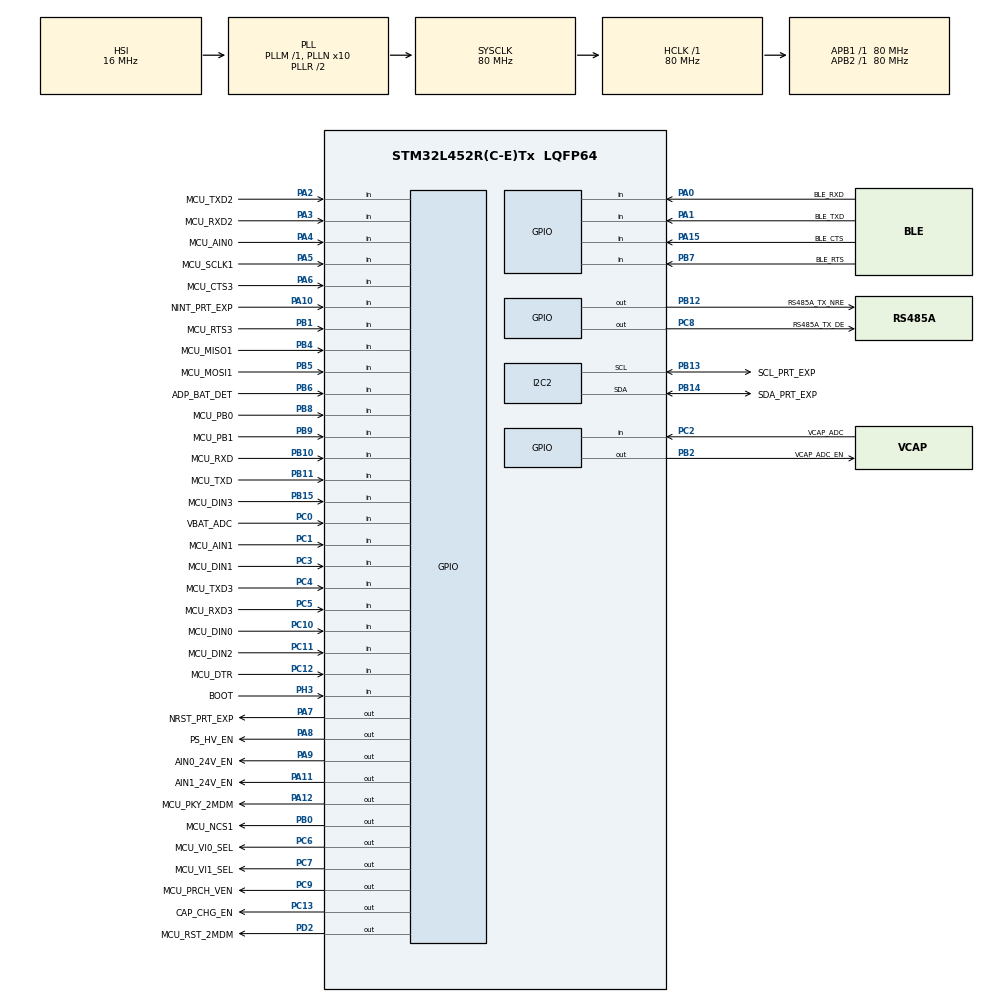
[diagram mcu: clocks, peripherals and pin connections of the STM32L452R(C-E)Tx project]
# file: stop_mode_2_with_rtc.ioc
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I2C2.Speed=10
I2C2.Timing=0xF010F3FE
Mcu.Family=STM32L4
Mcu.Name=STM32L452R(C-E)Tx
Mcu.Package=LQFP64
NVIC.I2C2_ER_IRQn=true\:0\:0\:false\:false\:true\:true\:true
NVIC.I2C2_EV_IRQn=true\:0\:0\:false\:false\:true\:true\:true
NVIC.PriorityGroup=NVIC_PRIORITYGROUP_4
PA0.GPIO_Label=BLE_RXD
PA0.GPIO_PuPd=GPIO_PULLUP
PA0.Signal=GPIO_Input
PA1.GPIO_Label=BLE_TXD
PA1.GPIO_PuPd=GPIO_PULLUP
PA1.Signal=GPIO_Input
PA10.GPIO_Label=NINT_PRT_EXP
PA10.GPIO_PuPd=GPIO_PULLUP
PA10.Signal=GPIO_Input
PA11.GPIO_Label=AIN1_24V_EN
PA11.GPIO_PuPd=GPIO_NOPULL
PA11.PinState=GPIO_PIN_RESET
PA11.Signal=GPIO_Output
PA12.GPIO_Label=MCU_PKY_2MDM
PA12.Signal=GPIO_Output
PA13\ (JTMS/SWDIO).GPIO_Label=TMS
PA13\ (JTMS/SWDIO).Mode=Trace_Asynchronous_SW
PA13\ (JTMS/SWDIO).Signal=SYS_JTMS-SWDIO
PA14\ (JTCK/SWCLK).GPIO_Label=TCK
PA14\ (JTCK/SWCLK).Mode=Trace_Asynchronous_SW
PA14\ (JTCK/SWCLK).Signal=SYS_JTCK-SWCLK
PA15\ (JTDI).GPIO_Label=BLE_CTS
PA15\ (JTDI).GPIO_PuPd=GPIO_PULLUP
PA15\ (JTDI).Signal=GPIO_Input
PA2.GPIO_Label=MCU_TXD2
PA2.GPIO_PuPd=GPIO_PULLUP
PA2.Signal=GPIO_Input
PA3.GPIO_Label=MCU_RXD2
PA3.GPIO_PuPd=GPIO_PULLUP
PA3.Signal=GPIO_Input
PA4.GPIO_Label=MCU_AIN0
PA4.Signal=GPIO_Input
PA5.GPIO_Label=MCU_SCLK1
PA5.GPIO_PuPd=GPIO_PULLUP
PA5.Signal=GPIO_Input
PA6.GPIO_Label=MCU_CTS3
PA6.GPIO_PuPd=GPIO_PULLUP
PA6.Signal=GPIO_Input
PA7.GPIO_Label=NRST_PRT_EXP
PA7.GPIO_PuPd=GPIO_NOPULL
PA7.GPIO_Speed=GPIO_SPEED_FREQ_LOW
PA7.PinState=GPIO_PIN_SET
PA7.Signal=GPIO_Output
PA8.GPIO_Label=PS_HV_EN
PA8.PinState=GPIO_PIN_RESET
PA8.Signal=GPIO_Output
PA9.GPIO_Label=AIN0_24V_EN
PA9.Signal=GPIO_Output
PB0.GPIO_Label=MCU_NCS1
PB0.PinState=GPIO_PIN_SET
PB0.Signal=GPIO_Output
PB1.GPIO_Label=MCU_RTS3
PB1.GPIO_PuPd=GPIO_PULLUP
PB1.Signal=GPIO_Input
PB10.GPIO_Label=MCU_RXD
PB10.GPIO_PuPd=GPIO_PULLUP
PB10.Signal=GPIO_Input
PB11.GPIO_Label=MCU_TXD
PB11.GPIO_PuPd=GPIO_PULLUP
PB11.Signal=GPIO_Input
PB12.GPIO_Label=RS485A_TX_NRE
PB12.PinState=GPIO_PIN_SET
PB12.Signal=GPIO_Output
PB13.GPIO_Label=SCL_PRT_EXP
PB13.Mode=I2C
PB13.Signal=I2C2_SCL
PB14.GPIO_Label=SDA_PRT_EXP
PB14.Mode=I2C
PB14.Signal=I2C2_SDA
PB15.GPIO_Label=MCU_DIN3
PB15.GPIO_PuPd=GPIO_PULLUP
PB15.Signal=GPIO_Input
PB2.GPIO_Label=VCAP_ADC_EN
PB2.Signal=GPIO_Output
PB3\ (JTDO/TRACESWO).GPIO_Label=SWO
PB3\ (JTDO/TRACESWO).Mode=Trace_Asynchronous_SW
PB3\ (JTDO/TRACESWO).Signal=SYS_JTDO-SWO
PB4\ (NJTRST).GPIO_Label=MCU_MISO1
PB4\ (NJTRST).GPIO_PuPd=GPIO_PULLUP
PB4\ (NJTRST).Signal=GPIO_Input
PB5.GPIO_Label=MCU_MOSI1
PB5.GPIO_PuPd=GPIO_PULLUP
PB5.Signal=GPIO_Input
PB6.GPIO_Label=ADP_BAT_DET
PB6.Signal=GPIO_Input
PB7.GPIO_Label=BLE_RTS
PB7.GPIO_PuPd=GPIO_PULLUP
PB7.Signal=GPIO_Input
PB8.GPIO_Label=MCU_PB0
PB8.GPIO_PuPd=GPIO_PULLUP
PB8.Signal=GPIO_Input
PB9.GPIO_Label=MCU_PB1
PB9.GPIO_PuPd=GPIO_PULLUP
PB9.Signal=GPIO_Input
PC0.GPIO_Label=VBAT_ADC
PC0.Signal=GPIO_Input
PC1.GPIO_Label=MCU_AIN1
PC1.Signal=GPIO_Input
PC10.GPIO_Label=MCU_DIN0
PC10.GPIO_PuPd=GPIO_PULLUP
PC10.Signal=GPIO_Input
PC11.GPIO_Label=MCU_DIN2
PC11.GPIO_PuPd=GPIO_PULLUP
PC11.Signal=GPIO_Input
PC12.GPIO_Label=MCU_DTR
PC12.GPIO_PuPd=GPIO_PULLUP
PC12.Signal=GPIO_Input
PC13.GPIO_Label=CAP_CHG_EN
PC13.Signal=GPIO_Output
PC14-OSC32_IN\ (PC14).Mode=LSE-External-Oscillator
PC14-OSC32_IN\ (PC14).Signal=RCC_OSC32_IN
PC15-OSC32_OUT\ (PC15).Mode=LSE-External-Oscillator
PC15-OSC32_OUT\ (PC15).Signal=RCC_OSC32_OUT
PC2.GPIO_Label=VCAP_ADC
PC2.Signal=GPIO_Input
PC3.GPIO_Label=MCU_DIN1
PC3.GPIO_PuPd=GPIO_PULLUP
PC3.Signal=GPIO_Input
PC4.GPIO_Label=MCU_TXD3
PC4.GPIO_PuPd=GPIO_PULLUP
PC4.Signal=GPIO_Input
PC5.GPIO_Label=MCU_RXD3
PC5.GPIO_PuPd=GPIO_PULLUP
PC5.Signal=GPIO_Input
PC6.GPIO_Label=MCU_VI0_SEL
PC6.Signal=GPIO_Output
PC7.GPIO_Label=MCU_VI1_SEL
PC7.Signal=GPIO_Output
PC8.GPIO_Label=RS485A_TX_DE
PC8.Signal=GPIO_Output
PC9.GPIO_Label=MCU_PRCH_VEN
PC9.Signal=GPIO_Output
PD2.GPIO_Label=MCU_RST_2MDM
PD2.Signal=GPIO_Output
PH0-OSC_IN\ (PH0).Signal=RCC_OSC_IN
PH1-OSC_OUT\ (PH1).Signal=RCC_OSC_OUT
PH3-BOOT0\ (BOOT0).GPIO_Label=BOOT
PH3-BOOT0\ (BOOT0).Signal=GPIO_Input
ProjectManager.HeapSize=0x200
ProjectManager.StackSize=0x400
ProjectManager.TargetToolchain=STM32CubeIDE
RCC.ADCFreq_Value=64000000
RCC.AHBFreq_Value=80000000
RCC.APB1Freq_Value=80000000
RCC.APB1TimFreq_Value=80000000
RCC.APB2Freq_Value=80000000
RCC.APB2TimFreq_Value=80000000
RCC.CortexFreq_Value=80000000
RCC.HCLKFreq_Value=80000000
RCC.HSE_VALUE=8000000
RCC.HSI48_VALUE=48000000
RCC.HSI_VALUE=16000000
RCC.MSI_VALUE=4000000
RCC.PLLN=10
RCC.PLLSourceVirtual=RCC_PLLSOURCE_HSI
RCC.PREFETCH_ENABLE=1
RCC.SYSCLKFreq_VALUE=80000000
RCC.SYSCLKSource=RCC_SYSCLKSOURCE_PLLCLK
RCC.USBFreq_Value=64000000
RCC.VCOOutputFreq_Value=160000000
board=NUCLEO-L452RE

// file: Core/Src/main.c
/* USER CODE BEGIN Header */
/**
  ******************************************************************************
  * @file           : main.c
  * @brief          : Main program body
  ******************************************************************************
  * @attention
  *
  * <h2><center>&copy; Copyright (c) 2020 STMicroelectronics.
  * All rights reserved.</center></h2>
  *
  * This software component is licensed by ST under BSD 3-Clause license,
  * the "License"; You may not use this file except in compliance with the
  * License. You may obtain a copy of the License at:
  *                        opensource.org/licenses/BSD-3-Clause
  *
  ******************************************************************************
  */
/* USER CODE END Header */

#include "main.h"

I2C_HandleTypeDef hi2c2;

void SystemClock_Config(void);
static void MX_GPIO_Init(void);
static void MX_I2C2_Init(void);

int main(void)
{

  /* MCU Configuration--------------------------------------------------------*/

  /* Reset of all peripherals, Initializes the Flash interface and the Systick. */
  HAL_Init();

  /* Configure the system clock */
  SystemClock_Config();

  /* Initialize all configured peripherals */
  MX_GPIO_Init();
  MX_I2C2_Init();
  /* USER CODE BEGIN 2 */
	HAL_Delay(10000);
  /* USER CODE END 2 */

  /* Infinite loop */
  while (1)
  {

    /* USER CODE BEGIN 3 */
	/* Enter STOP 2 mode */
	HAL_PWREx_EnterSTOP2Mode(PWR_STOPENTRY_WFI);
  }
  /* USER CODE END 3 */
}

void SystemClock_Config(void)
{
  RCC_OscInitTypeDef RCC_OscInitStruct = {0};
  RCC_ClkInitTypeDef RCC_ClkInitStruct = {0};
  RCC_PeriphCLKInitTypeDef PeriphClkInit = {0};

  /** Initializes the CPU, AHB and APB busses clocks
  */
  RCC_OscInitStruct.OscillatorType = RCC_OSCILLATORTYPE_HSI;
  RCC_OscInitStruct.HSIState = RCC_HSI_ON;
  RCC_OscInitStruct.HSICalibrationValue = RCC_HSICALIBRATION_DEFAULT;
  RCC_OscInitStruct.PLL.PLLState = RCC_PLL_ON;
  RCC_OscInitStruct.PLL.PLLSource = RCC_PLLSOURCE_HSI;
  RCC_OscInitStruct.PLL.PLLM = 1;
  RCC_OscInitStruct.PLL.PLLN = 10;
  RCC_OscInitStruct.PLL.PLLP = RCC_PLLP_DIV7;
  RCC_OscInitStruct.PLL.PLLQ = RCC_PLLQ_DIV2;
  RCC_OscInitStruct.PLL.PLLR = RCC_PLLR_DIV2;
  if (HAL_RCC_OscConfig(&RCC_OscInitStruct) != HAL_OK)
  {
    Error_Handler();
  }
  /** Initializes the CPU, AHB and APB busses clocks
  */
  RCC_ClkInitStruct.ClockType = RCC_CLOCKTYPE_HCLK|RCC_CLOCKTYPE_SYSCLK
                              |RCC_CLOCKTYPE_PCLK1|RCC_CLOCKTYPE_PCLK2;
  RCC_ClkInitStruct.SYSCLKSource = RCC_SYSCLKSOURCE_PLLCLK;
  RCC_ClkInitStruct.AHBCLKDivider = RCC_SYSCLK_DIV1;
  RCC_ClkInitStruct.APB1CLKDivider = RCC_HCLK_DIV1;
  RCC_ClkInitStruct.APB2CLKDivider = RCC_HCLK_DIV1;

  if (HAL_RCC_ClockConfig(&RCC_ClkInitStruct, FLASH_LATENCY_4) != HAL_OK)
  {
    Error_Handler();
  }
  PeriphClkInit.PeriphClockSelection = RCC_PERIPHCLK_I2C2;
  PeriphClkInit.I2c2ClockSelection = RCC_I2C2CLKSOURCE_PCLK1;
  if (HAL_RCCEx_PeriphCLKConfig(&PeriphClkInit) != HAL_OK)
  {
    Error_Handler();
  }
  /** Configure the main internal regulator output voltage
  */
  if (HAL_PWREx_ControlVoltageScaling(PWR_REGULATOR_VOLTAGE_SCALE1) != HAL_OK)
  {
    Error_Handler();
  }
}

static void MX_I2C2_Init(void)
{

  hi2c2.Instance = I2C2;
  hi2c2.Init.Timing = 0xF010F3FE;
  hi2c2.Init.OwnAddress1 = 0;
  hi2c2.Init.AddressingMode = I2C_ADDRESSINGMODE_7BIT;
  hi2c2.Init.DualAddressMode = I2C_DUALADDRESS_DISABLE;
  hi2c2.Init.OwnAddress2 = 0;
  hi2c2.Init.OwnAddress2Masks = I2C_OA2_NOMASK;
  hi2c2.Init.GeneralCallMode = I2C_GENERALCALL_DISABLE;
  hi2c2.Init.NoStretchMode = I2C_NOSTRETCH_DISABLE;
  if (HAL_I2C_Init(&hi2c2) != HAL_OK)
  {
    Error_Handler();
  }
  /** Configure Analogue filter
  */
  if (HAL_I2CEx_ConfigAnalogFilter(&hi2c2, I2C_ANALOGFILTER_ENABLE) != HAL_OK)
  {
    Error_Handler();
  }
  /** Configure Digital filter
  */
  if (HAL_I2CEx_ConfigDigitalFilter(&hi2c2, 0) != HAL_OK)
  {
    Error_Handler();
  }

}

static void MX_GPIO_Init(void)
{
  GPIO_InitTypeDef GPIO_InitStruct = {0};

  /* GPIO Ports Clock Enable */
  __HAL_RCC_GPIOC_CLK_ENABLE();
  __HAL_RCC_GPIOH_CLK_ENABLE();
  __HAL_RCC_GPIOA_CLK_ENABLE();
  __HAL_RCC_GPIOB_CLK_ENABLE();
  __HAL_RCC_GPIOD_CLK_ENABLE();

  /*Configure GPIO pin Output Level */
  HAL_GPIO_WritePin(GPIOC, CAP_CHG_EN_Pin|MCU_VI0_SEL_Pin|MCU_VI1_SEL_Pin|RS485A_TX_DE_Pin
                          |MCU_PRCH_VEN_Pin, GPIO_PIN_RESET);

  /*Configure GPIO pin Output Level */
  HAL_GPIO_WritePin(NRST_PRT_EXP_GPIO_Port, NRST_PRT_EXP_Pin, GPIO_PIN_SET);

  /*Configure GPIO pin Output Level */
  HAL_GPIO_WritePin(GPIOB, MCU_NCS1_Pin|RS485A_TX_NRE_Pin, GPIO_PIN_SET);

  /*Configure GPIO pin Output Level */
  HAL_GPIO_WritePin(VCAP_ADC_EN_GPIO_Port, VCAP_ADC_EN_Pin, GPIO_PIN_RESET);

  /*Configure GPIO pin Output Level */
  HAL_GPIO_WritePin(GPIOA, PS_HV_EN_Pin|AIN0_24V_EN_Pin|AIN1_24V_EN_Pin|MCU_PKY_2MDM_Pin, GPIO_PIN_RESET);

  /*Configure GPIO pin Output Level */
  HAL_GPIO_WritePin(MCU_RST_2MDM_GPIO_Port, MCU_RST_2MDM_Pin, GPIO_PIN_RESET);

  /*Configure GPIO pins : CAP_CHG_EN_Pin MCU_VI0_SEL_Pin MCU_VI1_SEL_Pin RS485A_TX_DE_Pin
                           MCU_PRCH_VEN_Pin */
  GPIO_InitStruct.Pin = CAP_CHG_EN_Pin|MCU_VI0_SEL_Pin|MCU_VI1_SEL_Pin|RS485A_TX_DE_Pin
                          |MCU_PRCH_VEN_Pin;
  GPIO_InitStruct.Mode = GPIO_MODE_OUTPUT_PP;
  GPIO_InitStruct.Pull = GPIO_NOPULL;
  GPIO_InitStruct.Speed = GPIO_SPEED_FREQ_LOW;
  HAL_GPIO_Init(GPIOC, &GPIO_InitStruct);

  /*Configure GPIO pins : VBAT_ADC_Pin MCU_AIN1_Pin VCAP_ADC_Pin */
  GPIO_InitStruct.Pin = VBAT_ADC_Pin|MCU_AIN1_Pin|VCAP_ADC_Pin;
  GPIO_InitStruct.Mode = GPIO_MODE_INPUT;
  GPIO_InitStruct.Pull = GPIO_NOPULL;
  HAL_GPIO_Init(GPIOC, &GPIO_InitStruct);

  /*Configure GPIO pins : MCU_DIN1_Pin MCU_TXD3_Pin MCU_RXD3_Pin MCU_DIN0_Pin
                           MCU_DIN2_Pin MCU_DTR_Pin */
  GPIO_InitStruct.Pin = MCU_DIN1_Pin|MCU_TXD3_Pin|MCU_RXD3_Pin|MCU_DIN0_Pin
                          |MCU_DIN2_Pin|MCU_DTR_Pin;
  GPIO_InitStruct.Mode = GPIO_MODE_INPUT;
  GPIO_InitStruct.Pull = GPIO_PULLUP;
  HAL_GPIO_Init(GPIOC, &GPIO_InitStruct);

  /*Configure GPIO pins : BLE_RXD_Pin BLE_TXD_Pin MCU_TXD2_Pin MCU_RXD2_Pin
                           MCU_SCLK1_Pin MCU_CTS3_Pin NINT_PRT_EXP_Pin BLE_CTS_Pin */
  GPIO_InitStruct.Pin = BLE_RXD_Pin|BLE_TXD_Pin|MCU_TXD2_Pin|MCU_RXD2_Pin
                          |MCU_SCLK1_Pin|MCU_CTS3_Pin|NINT_PRT_EXP_Pin|BLE_CTS_Pin;
  GPIO_InitStruct.Mode = GPIO_MODE_INPUT;
  GPIO_InitStruct.Pull = GPIO_PULLUP;
  HAL_GPIO_Init(GPIOA, &GPIO_InitStruct);

  /*Configure GPIO pin : MCU_AIN0_Pin */
  GPIO_InitStruct.Pin = MCU_AIN0_Pin;
  GPIO_InitStruct.Mode = GPIO_MODE_INPUT;
  GPIO_InitStruct.Pull = GPIO_NOPULL;
  HAL_GPIO_Init(MCU_AIN0_GPIO_Port, &GPIO_InitStruct);

  /*Configure GPIO pins : NRST_PRT_EXP_Pin PS_HV_EN_Pin AIN0_24V_EN_Pin AIN1_24V_EN_Pin
                           MCU_PKY_2MDM_Pin */
  GPIO_InitStruct.Pin = NRST_PRT_EXP_Pin|PS_HV_EN_Pin|AIN0_24V_EN_Pin|AIN1_24V_EN_Pin
                          |MCU_PKY_2MDM_Pin;
  GPIO_InitStruct.Mode = GPIO_MODE_OUTPUT_PP;
  GPIO_InitStruct.Pull = GPIO_NOPULL;
  GPIO_InitStruct.Speed = GPIO_SPEED_FREQ_LOW;
  HAL_GPIO_Init(GPIOA, &GPIO_InitStruct);

  /*Configure GPIO pins : MCU_NCS1_Pin VCAP_ADC_EN_Pin RS485A_TX_NRE_Pin */
  GPIO_InitStruct.Pin = MCU_NCS1_Pin|VCAP_ADC_EN_Pin|RS485A_TX_NRE_Pin;
  GPIO_InitStruct.Mode = GPIO_MODE_OUTPUT_PP;
  GPIO_InitStruct.Pull = GPIO_NOPULL;
  GPIO_InitStruct.Speed = GPIO_SPEED_FREQ_LOW;
  HAL_GPIO_Init(GPIOB, &GPIO_InitStruct);

  /*Configure GPIO pins : MCU_RTS3_Pin MCU_RXD_Pin MCU_TXD_Pin MCU_DIN3_Pin
                           MCU_MISO1_Pin MCU_MOSI1_Pin BLE_RTS_Pin MCU_PB0_Pin
                           MCU_PB1_Pin */
  GPIO_InitStruct.Pin = MCU_RTS3_Pin|MCU_RXD_Pin|MCU_TXD_Pin|MCU_DIN3_Pin
                          |MCU_MISO1_Pin|MCU_MOSI1_Pin|BLE_RTS_Pin|MCU_PB0_Pin
                          |MCU_PB1_Pin;
  GPIO_InitStruct.Mode = GPIO_MODE_INPUT;
  GPIO_InitStruct.Pull = GPIO_PULLUP;
  HAL_GPIO_Init(GPIOB, &GPIO_InitStruct);

  /*Configure GPIO pin : MCU_RST_2MDM_Pin */
  GPIO_InitStruct.Pin = MCU_RST_2MDM_Pin;
  GPIO_InitStruct.Mode = GPIO_MODE_OUTPUT_PP;
  GPIO_InitStruct.Pull = GPIO_NOPULL;
  GPIO_InitStruct.Speed = GPIO_SPEED_FREQ_LOW;
  HAL_GPIO_Init(MCU_RST_2MDM_GPIO_Port, &GPIO_InitStruct);

  /*Configure GPIO pin : ADP_BAT_DET_Pin */
  GPIO_InitStruct.Pin = ADP_BAT_DET_Pin;
  GPIO_InitStruct.Mode = GPIO_MODE_INPUT;
  GPIO_InitStruct.Pull = GPIO_NOPULL;
  HAL_GPIO_Init(ADP_BAT_DET_GPIO_Port, &GPIO_InitStruct);

  /*Configure GPIO pin : BOOT_Pin */
  GPIO_InitStruct.Pin = BOOT_Pin;
  GPIO_InitStruct.Mode = GPIO_MODE_INPUT;
  GPIO_InitStruct.Pull = GPIO_NOPULL;
  HAL_GPIO_Init(BOOT_GPIO_Port, &GPIO_InitStruct);

}

void Error_Handler(void)
{
}

/************************ (C) COPYRIGHT STMicroelectronics *****END OF FILE****/
